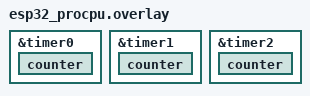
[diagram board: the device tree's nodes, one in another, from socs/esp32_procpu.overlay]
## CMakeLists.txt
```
# SPDX-License-Identifier: Apache-2.0

cmake_minimum_required(VERSION 3.28.0)

find_package(Zephyr REQUIRED HINTS $ENV{ZEPHYR_BASE})
project(esp_interrupt_test)

target_sources(app PRIVATE src/main.c src/noniram.c src/mli_encoding.c src/mli_dispatch.c)
target_include_directories(app PRIVATE ${ZEPHYR_BASE}/arch/common/include)
```

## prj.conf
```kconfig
CONFIG_ZTEST=y
CONFIG_COUNTER=y
CONFIG_DYNAMIC_INTERRUPTS=y
```

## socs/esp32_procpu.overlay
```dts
/*
 * Copyright (c) 2025-2026 Espressif Systems (Shanghai) Co., Ltd.
 *
 * SPDX-License-Identifier: Apache-2.0
 */

/*
 * Only enable the timers; their interrupt wiring is inherited from
 * esp32_common.dtsi, which routes each one through its own INTMUX node with a
 * single interrupt cell. Do not override "interrupts" here: the pre-INTMUX
 * <cpu_line source priority flags> form parses as four separate interrupts
 * against a 1-cell intmux and makes gen_isr_tables.py reject the build.
 */

&timer0 {
	status = "okay";

	counter {
		status = "okay";
	};
};

&timer1 {
	status = "okay";

	counter {
		status = "okay";
	};
};

&timer2 {
	status = "okay";

	counter {
		status = "okay";
	};
};
```

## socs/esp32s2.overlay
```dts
/*
 * Copyright (c) 2025-2026 Espressif Systems (Shanghai) Co., Ltd.
 *
 * SPDX-License-Identifier: Apache-2.0
 */

/*
 * Only enable the timers; their interrupt wiring is inherited from
 * esp32s2_common.dtsi, which routes each one through its own INTMUX node with a
 * single interrupt cell. Do not override "interrupts" here: the pre-INTMUX
 * <cpu_line source priority flags> form parses as four separate interrupts
 * against a 1-cell intmux and makes gen_isr_tables.py reject the build.
 */

&timer0 {
	status = "okay";

	counter {
		status = "okay";
	};
};

&timer1 {
	status = "okay";

	counter {
		status = "okay";
	};
};

&timer2 {
	status = "okay";

	counter {
		status = "okay";
	};
};
```

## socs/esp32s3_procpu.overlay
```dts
/*
 * Copyright (c) 2025 Espressif Systems (Shanghai) Co., Ltd.
 *
 * SPDX-License-Identifier: Apache-2.0
 */

&timer0 {
	status = "okay";

	counter {
		status = "okay";
	};
};

&timer1 {
	status = "okay";

	counter {
		status = "okay";
	};
};

&timer2 {
	status = "okay";

	counter {
		status = "okay";
	};
};
```

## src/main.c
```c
/*
 * Copyright (c) 2025 Espressif Systems (Shanghai) Co., Ltd.
 *
 * SPDX-License-Identifier: Apache-2.0
 */

#include <zephyr/kernel.h>
#include <zephyr/ztest.h>
#include <zephyr/device.h>
#include <zephyr/devicetree.h>
#include <zephyr/drivers/counter.h>
#include <zephyr/sys/printk.h>

#define COUNTER_INST_COUNT DT_NUM_INST_STATUS_OKAY(espressif_esp32_counter)

#if COUNTER_INST_COUNT >= 3

/* Test sets the three timer units, each with different interrupt priority level.
 * Each timer/counter is set to respond to three separate alarms.
 * The alarm times are set so each would trigger one after another separated by
 * the `ALARM_DIFF_US` time.
 * Each ISR sets its corresponding token into its token slots and wait for the
 * subsequent alarm ISR to be called.
 * After the last alarm ISR finishes the main loop checks if the ISR were called.
 */

#define TOKEN_A 0xBEEFBABE
#define TOKEN_B 0xC0FEB00B
#define TOKEN_C 0xDEAD5AA5

#define ALARM_DIFF_US 1000
#define ALARM_A_US    (1000 + ALARM_DIFF_US)
#define ALARM_B_US    (ALARM_A_US + ALARM_DIFF_US)
#define ALARM_C_US    (ALARM_B_US + ALARM_DIFF_US)
#define ISR_DELAY_US  (ALARM_DIFF_US * 3)
#define CYCLE_MS      10
#define TEST_CYCLES   1000

static const struct device *const timer0 = DEVICE_DT_GET(DT_INST(0, espressif_esp32_counter));
static const struct device *const timer1 = DEVICE_DT_GET(DT_INST(1, espressif_esp32_counter));
static const struct device *const timer2 = DEVICE_DT_GET(DT_INST(2, espressif_esp32_counter));

static struct counter_alarm_cfg alarm_a;
static struct counter_alarm_cfg alarm_b;
static struct counter_alarm_cfg alarm_c;

static int token[3];
static int success_cnt;
static int error_cnt;

static void alarm_handler_c(const struct device *dev, uint8_t chan_id, uint32_t counter,
			    void *user_data)
{
	if (dev == timer2 && token[0] == TOKEN_A && token[1] == TOKEN_B && token[2] == 0) {
		token[2] = TOKEN_C;
	}

	k_busy_wait(ISR_DELAY_US);
}

static void alarm_handler_b(const struct device *dev, uint8_t chan_id, uint32_t counter,
			    void *user_data)
{
	if (dev == timer1 && token[0] == TOKEN_A && token[1] == 0 && token[2] == 0) {
		token[1] = TOKEN_B;
	}

	k_busy_wait(ISR_DELAY_US);
}

static void alarm_handler_a(const struct device *dev, uint8_t chan_id, uint32_t counter,
			    void *user_data)
{
	if (dev == timer0 && token[0] == 0 && token[1] == 0 && token[2] == 0) {
		token[0] = TOKEN_A;
	}

	k_busy_wait(ISR_DELAY_US);
}

static void *esp_interrupt_suite_setup(void)
{
	zassert_true(device_is_ready(timer0), "Device %s not ready", timer0->name);
	zassert_true(device_is_ready(timer1), "Device %s not ready", timer1->name);
	zassert_true(device_is_ready(timer2), "Device %s not ready", timer2->name);

	zassert_false(counter_start(timer0), "Timer 0 failed to start");
	zassert_false(counter_start(timer1), "Timer 1 failed to start");
	zassert_false(counter_start(timer2), "Timer 2 failed to start");

	return NULL;
}


ZTEST(esp_interrupt, test_nested_isr)
{
	uint32_t cnt = TEST_CYCLES;

	success_cnt = 0;
	error_cnt = 0;

	while (cnt--) {
		alarm_a.ticks = counter_us_to_ticks(timer0, ALARM_A_US);
		alarm_a.callback = alarm_handler_a;

		alarm_b.ticks = counter_us_to_ticks(timer1, ALARM_B_US);
		alarm_b.callback = alarm_handler_b;

		alarm_c.ticks = counter_us_to_ticks(timer2, ALARM_C_US);
		alarm_c.callback = alarm_handler_c;

		counter_reset(timer0);
		counter_reset(timer1);
		counter_reset(timer2);

		zassert_false(counter_set_channel_alarm(timer0, 0, &alarm_a),
			      "Failed to set alarm A");
		zassert_false(counter_set_channel_alarm(timer1, 0, &alarm_b),
			      "Failed to set alarm B");
		zassert_false(counter_set_channel_alarm(timer2, 0, &alarm_c),
			      "Failed to set alarm C");

		k_msleep(CYCLE_MS);

		if (token[0] == TOKEN_A && token[1] == TOKEN_B && token[2] == TOKEN_C) {
			success_cnt++;
		} else {
			error_cnt++;
		}

		token[0] = 0;
		token[1] = 0;
		token[2] = 0;
	}

	zassert_true(error_cnt == 0, "Errors occurred (%d)", error_cnt);
	zassert_true(success_cnt == TEST_CYCLES, "Not all test cycles passed (%d from %d)",
		     success_cnt, TEST_CYCLES);
}

ZTEST_SUITE(esp_interrupt, NULL, esp_interrupt_suite_setup, NULL, NULL, NULL);

#endif /* COUNTER_INST_COUNT >= 3 */
```

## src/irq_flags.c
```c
/*
 * Copyright (c) 2026 Espressif Systems (Shanghai) Co., Ltd.
 *
 * SPDX-License-Identifier: Apache-2.0
 */

#include <zephyr/ztest.h>
#include <zephyr/irq.h>
#include <zephyr/sw_isr_table.h>
#include <esp_attr.h>
#include <esp_soc_irq.h>
#include <zephyr/drivers/interrupt_controller/intc_esp32.h>

#define TEST_IRQ_PRIORITY 1

static volatile int iram_isr_count;

static void IRAM_ATTR test_isr_iram_a(const void *arg)
{
	ARG_UNUSED(arg);
	iram_isr_count++;
}

static void IRAM_ATTR test_isr_iram_b(const void *arg)
{
	ARG_UNUSED(arg);
	iram_isr_count++;
}

static void test_isr_flash(const void *arg)
{
	ARG_UNUSED(arg);
	iram_isr_count++;
}

/*
 * Find a free CPU interrupt line. The search is bounded by SOC_CPU_INTR_NUM and
 * not by CONFIG_NUM_IRQS: only the first SOC_CPU_INTR_NUM table entries are CPU
 * lines, the rest being the level-2 source window and the level-3 windows. The
 * IRAM bookkeeping under test is indexed by CPU line, so handing it a slot from
 * one of the higher windows is meaningless and is rejected.
 */
static unsigned int find_unused_irq(void)
{
	unsigned int line;

	for (line = 0; line < SOC_CPU_INTR_NUM; line++) {
		unsigned int table_idx = line + CONFIG_GEN_IRQ_START_VECTOR;

		if (_sw_isr_table[table_idx].isr == z_irq_spurious) {
			return line;
		}
	}

	zassert_unreachable("No unused CPU interrupt line found");
	return 0;
}

ZTEST(esp_irq_flags, test_shared_iram_line_mask)
{
	unsigned int irq = find_unused_irq();
	int rc;

	rc = arch_irq_connect_dynamic(irq, TEST_IRQ_PRIORITY, test_isr_iram_a, NULL,
				      ESP_INTR_FLAG_IRAM);
	zassert_equal(rc, (int)irq, "first IRAM connect failed: %d", rc);
	zassert_equal(z_soc_irq_line_total_clients_get(irq), 1);
	zassert_equal(z_soc_irq_line_non_iram_clients_get(irq), 0);
	zassert_equal(z_soc_irq_non_iram_int_mask_get(irq), 0);

	rc = arch_irq_connect_dynamic(irq, TEST_IRQ_PRIORITY, test_isr_iram_b, NULL,
				      ESP_INTR_FLAG_IRAM);
	zassert_equal(rc, (int)irq, "second IRAM connect failed: %d", rc);
	zassert_equal(z_soc_irq_line_total_clients_get(irq), 2);
	zassert_equal(z_soc_irq_line_non_iram_clients_get(irq), 0);
	zassert_equal(z_soc_irq_non_iram_int_mask_get(irq), 0);

	rc = arch_irq_disconnect_dynamic(irq, TEST_IRQ_PRIORITY, test_isr_iram_a, NULL,
				       ESP_INTR_FLAG_IRAM);
	zassert_equal(rc, 0, "first IRAM disconnect failed: %d", rc);
	zassert_equal(z_soc_irq_line_total_clients_get(irq), 1);
	zassert_equal(z_soc_irq_non_iram_int_mask_get(irq), 0);

	rc = arch_irq_disconnect_dynamic(irq, TEST_IRQ_PRIORITY, test_isr_iram_b, NULL,
				       ESP_INTR_FLAG_IRAM);
	zassert_equal(rc, 0, "second IRAM disconnect failed: %d", rc);
	zassert_equal(z_soc_irq_line_total_clients_get(irq), 0);
	zassert_equal(z_soc_irq_non_iram_int_mask_get(irq), 0);
}

ZTEST(esp_irq_flags, test_shared_mixed_registration_rejected)
{
	unsigned int irq = find_unused_irq();
	int rc;

	rc = arch_irq_connect_dynamic(irq, TEST_IRQ_PRIORITY, test_isr_iram_a, NULL,
				      ESP_INTR_FLAG_IRAM);
	zassert_equal(rc, (int)irq, "IRAM connect failed: %d", rc);

	rc = arch_irq_connect_dynamic(irq, TEST_IRQ_PRIORITY, test_isr_flash, NULL, 0);
	zassert_equal(rc, -EINVAL, "mixed non-IRAM connect should fail");
	zassert_equal(z_soc_irq_line_total_clients_get(irq), 1);
	zassert_equal(z_soc_irq_non_iram_int_mask_get(irq), 0);

	rc = arch_irq_disconnect_dynamic(irq, TEST_IRQ_PRIORITY, test_isr_iram_a, NULL,
				       ESP_INTR_FLAG_IRAM);
	zassert_equal(rc, 0, "IRAM disconnect failed: %d", rc);
}

ZTEST(esp_irq_flags, test_shared_non_iram_sets_mask)
{
	unsigned int irq = find_unused_irq();
	int rc;

	rc = arch_irq_connect_dynamic(irq, TEST_IRQ_PRIORITY, test_isr_flash, NULL, 0);
	zassert_equal(rc, (int)irq, "non-IRAM connect failed: %d", rc);
	zassert_equal(z_soc_irq_line_non_iram_clients_get(irq), 1);
	zassert_equal(z_soc_irq_non_iram_int_mask_get(irq), 1);

	rc = arch_irq_disconnect_dynamic(irq, TEST_IRQ_PRIORITY, test_isr_flash, NULL, 0);
	zassert_equal(rc, 0, "non-IRAM disconnect failed: %d", rc);
	zassert_equal(z_soc_irq_line_total_clients_get(irq), 0);
	zassert_equal(z_soc_irq_non_iram_int_mask_get(irq), 0);
}

ZTEST(esp_irq_flags, test_iram_flag_requires_iram_handler)
{
	unsigned int irq = find_unused_irq();
	int rc;

	rc = arch_irq_connect_dynamic(irq, TEST_IRQ_PRIORITY, test_isr_flash, NULL,
				      ESP_INTR_FLAG_IRAM);
	zassert_equal(rc, -EINVAL, "flash handler with IRAM flag should fail");
}

ZTEST_SUITE(esp_irq_flags, NULL, NULL, NULL, NULL, NULL);
```

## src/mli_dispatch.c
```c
/*
 * Copyright (c) 2026 Espressif Systems (Shanghai) Co., Ltd.
 *
 * SPDX-License-Identifier: Apache-2.0
 */

#include <zephyr/ztest.h>
#include <zephyr/devicetree.h>
#include <zephyr/irq.h>
#include <zephyr/irq_multilevel.h>
#include <zephyr/sw_isr_table.h>
#include <sw_isr_common.h>

#if defined(CONFIG_MULTI_LEVEL_INTERRUPTS)

/* A level-2 IRQ has its slot at the start of the level-2 window plus its source */
ZTEST(mli_dispatch, test_level_2_slot)
{
	const unsigned int irqn = DT_IRQN(DT_NODELABEL(uart0));

	zassert_equal(z_get_sw_isr_table_idx(irqn),
		      CONFIG_2ND_LVL_ISR_TBL_OFFSET + DT_IRQ(DT_NODELABEL(uart0), irq));
}

#if DT_HAS_COMPAT_STATUS_OKAY(espressif_esp32_counter)
#define COUNTER_IRQN DT_IRQN(DT_PARENT(DT_INST(0, espressif_esp32_counter)))

ZTEST(mli_dispatch, test_connected_level_2_slot)
{
	const unsigned int idx = z_get_sw_isr_table_idx(COUNTER_IRQN);

	zassert_not_equal(_sw_isr_table[idx].isr, z_irq_spurious,
			  "the counter ISR must sit in its level-2 slot");
}

ZTEST(mli_dispatch, test_enable_state)
{
	zassert_true(irq_is_enabled(COUNTER_IRQN) != 0, "the counter driver enables its IRQ");

	irq_disable(COUNTER_IRQN);
	zassert_true(irq_is_enabled(COUNTER_IRQN) == 0);

	irq_enable(COUNTER_IRQN);
	zassert_true(irq_is_enabled(COUNTER_IRQN) != 0);
}
#endif

#if defined(CONFIG_3RD_LEVEL_INTERRUPTS) && DT_NODE_HAS_STATUS_OKAY(DT_NODELABEL(gpio0_l3_intc))
/*
 * A level-3 IRQ has its slot in the window of its aggregator, at the input
 * index. The GPIO driver is connected on the catch-all input.
 */
ZTEST(mli_dispatch, test_level_3_catch_all_slot)
{
	const unsigned int irqn = DT_IRQN(DT_NODELABEL(gpio0));
	unsigned int idx = z_get_sw_isr_table_idx(irqn);

	zassert_true(idx >= CONFIG_3RD_LVL_ISR_TBL_OFFSET);
	zassert_equal((idx - CONFIG_3RD_LVL_ISR_TBL_OFFSET) %
			      CONFIG_MAX_IRQ_PER_3RD_LEVEL_AGGREGATOR,
		      irq_from_level_3(irqn));
	zassert_not_equal(_sw_isr_table[idx].isr, z_irq_spurious,
			  "the GPIO ISR must sit in the catch-all slot");
	idx = z_get_sw_isr_table_idx(DT_IRQN(DT_NODELABEL(gpio0_l3_intc)));
	zassert_not_equal(_sw_isr_table[idx].isr, z_irq_spurious,
			  "the aggregator ISR must sit in its level-2 slot");
}
#endif

ZTEST_SUITE(mli_dispatch, NULL, NULL, NULL, NULL, NULL);

#endif /* CONFIG_MULTI_LEVEL_INTERRUPTS */
```

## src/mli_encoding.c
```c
/*
 * Copyright (c) 2026 Espressif Systems (Shanghai) Co., Ltd.
 *
 * SPDX-License-Identifier: Apache-2.0
 */

#include <zephyr/ztest.h>
#include <zephyr/devicetree.h>
#include <zephyr/irq_multilevel.h>
#include <zephyr/drivers/interrupt_controller/intc_esp32.h>
#include <zephyr/dt-bindings/interrupt-controller/espressif-esp32-l3-intc.h>

#if defined(CONFIG_MULTI_LEVEL_INTERRUPTS)

/* Every level-2 and level-3 IRQ carries the intmux key line in its level-1 field */
#define INTMUX_KEY_LINE DT_IRQ(DT_NODELABEL(intmux), irq)

ZTEST(mli_encoding, test_shared_consumer_is_level_2)
{
	const unsigned int irqn = DT_IRQN(DT_NODELABEL(uart0));

	zassert_equal(irq_get_level(irqn), 2U);
	zassert_equal(irq_from_level_2(irqn), DT_IRQ(DT_NODELABEL(uart0), irq),
		      "level-2 field must be the interrupt matrix source");
	zassert_equal(irq_parent_level_2(irqn), INTMUX_KEY_LINE);
}

ZTEST(mli_encoding, test_flags_cell)
{
	zassert_equal(DT_IRQ(DT_NODELABEL(uart0), flags) & ESP_INTR_FLAG_IRAM, 0,
		      "uart0 must not be marked ESP_INTR_FLAG_IRAM");
#if DT_NODE_HAS_STATUS_OKAY(DT_NODELABEL(systimer0))
	zassert_not_equal(DT_IRQ(DT_NODELABEL(systimer0), flags) & ESP_INTR_FLAG_IRAM, 0,
			  "the system tick must be marked ESP_INTR_FLAG_IRAM");
#endif
}

#if defined(CONFIG_3RD_LEVEL_INTERRUPTS) &&                                                       \
	(DT_NODE_EXISTS(DT_NODELABEL(rtc_l3_intc)) || DT_NODE_EXISTS(DT_NODELABEL(gpio0_l3_intc)))

static void check_level_3(unsigned int irqn, unsigned int input, unsigned int source)
{
	zassert_equal(irq_get_level(irqn), 3U);
	zassert_equal(irq_from_level_3(irqn), input, "level-3 field must be the input index");
	zassert_equal(irq_from_level_2(irqn), source,
		      "level-2 field must be the aggregator's source");
	zassert_equal(irq_parent_level_2(irqn), INTMUX_KEY_LINE);
}

#if DT_NODE_EXISTS(DT_NODELABEL(rtc_l3_intc))
ZTEST(mli_encoding, test_rtc_timer_is_level_3)
{
	check_level_3(DT_IRQN(DT_NODELABEL(rtc_timer)), DT_IRQ(DT_NODELABEL(rtc_timer), irq),
		      DT_IRQ(DT_NODELABEL(rtc_l3_intc), irq));
}
#endif

#if DT_NODE_EXISTS(DT_NODELABEL(gpio0_l3_intc))
BUILD_ASSERT(DT_PROP_LAST(DT_NODELABEL(gpio0_l3_intc), bits) == ESP_L3_CATCH_ALL,
	     "the last gpio0_l3_intc input must be ESP_L3_CATCH_ALL");

ZTEST(mli_encoding, test_gpio_is_catch_all_input)
{
	const unsigned int source = DT_IRQ(DT_NODELABEL(gpio0_l3_intc), irq);

	check_level_3(DT_IRQN(DT_NODELABEL(gpio0)),
		      DT_PROP_LEN(DT_NODELABEL(gpio0_l3_intc), bits) - 1U, source);
	check_level_3(DT_IRQN(DT_NODELABEL(ana_cmpr0)), 0U, source);
}
#endif

#endif /* CONFIG_3RD_LEVEL_INTERRUPTS && level-3 consumers */

ZTEST_SUITE(mli_encoding, NULL, NULL, NULL, NULL, NULL);

#endif /* CONFIG_MULTI_LEVEL_INTERRUPTS */
```

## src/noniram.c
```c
/*
 * Copyright (c) 2026 Espressif Systems (Shanghai) Co., Ltd.
 *
 * SPDX-License-Identifier: Apache-2.0
 */

/*
 * esp_intr_noniram_disable() masks every CPU line not marked
 * ESP_INTR_FLAG_IRAM in the devicetree, and esp_intr_noniram_enable() unmasks
 * it. A timer group alarm is level-triggered and stays pending until its ISR
 * clears it, so an alarm raised during the pause fires once on resume. Nothing
 * is asserted while paused: a failed assertion would leave the pause active.
 */

#include <zephyr/ztest.h>
#include <zephyr/device.h>
#include <zephyr/devicetree.h>
#include <zephyr/irq.h>
#include <zephyr/drivers/counter.h>
#include <zephyr/drivers/interrupt_controller/intc_esp32.h>

#define COUNTER_NODE DT_INST(0, espressif_esp32_counter)

#if DT_NODE_HAS_STATUS_OKAY(COUNTER_NODE)

#define COUNTER_TIMER DT_PARENT(COUNTER_NODE)
#define COUNTER_IRQN  DT_IRQN(COUNTER_TIMER)
#define ALARM_US      100U
#define WAIT_US       2000U

BUILD_ASSERT((DT_IRQ(COUNTER_TIMER, flags) & ESP_INTR_FLAG_IRAM) == 0,
	     "the test needs a counter that is paused during flash operations");

static const struct device *const counter = DEVICE_DT_GET(COUNTER_NODE);
static volatile uint32_t alarm_hits;

static void alarm_cb(const struct device *dev, uint8_t chan_id, uint32_t ticks, void *user_data)
{
	ARG_UNUSED(dev);
	ARG_UNUSED(chan_id);
	ARG_UNUSED(ticks);
	ARG_UNUSED(user_data);

	alarm_hits++;
}

static int arm_alarm(void)
{
	struct counter_alarm_cfg cfg = {
		.callback = alarm_cb,
		.ticks = counter_us_to_ticks(counter, ALARM_US),
	};

	return counter_set_channel_alarm(counter, 0, &cfg);
}

static void esp_noniram_before(void *fixture)
{
	ARG_UNUSED(fixture);

	zassert_true(device_is_ready(counter), "Device %s not ready", counter->name);
	(void)counter_start(counter);
	irq_enable(COUNTER_IRQN);
	alarm_hits = 0U;
}

static void esp_noniram_after(void *fixture)
{
	ARG_UNUSED(fixture);

	(void)counter_cancel_channel_alarm(counter, 0);
	irq_enable(COUNTER_IRQN);
}

ZTEST(esp_noniram, test_paused_source_fires_on_resume)
{
	uint32_t hits_paused;
	int enabled_paused;
	int err;

	esp_intr_noniram_disable();
	err = arm_alarm();
	k_busy_wait(WAIT_US);
	hits_paused = alarm_hits;
	enabled_paused = irq_is_enabled(COUNTER_IRQN);
	esp_intr_noniram_enable();
	k_busy_wait(WAIT_US);

	zassert_equal(err, 0, "alarm not set: %d", err);
	zassert_equal(hits_paused, 0U, "the alarm fired while paused");
	zassert_not_equal(enabled_paused, 0, "a paused IRQ must read as enabled");
	zassert_equal(alarm_hits, 1U, "the alarm must fire once on resume");
}

ZTEST(esp_noniram, test_disable_while_paused_holds_on_resume)
{
	uint32_t hits_disabled;
	int enabled_disabled;
	int err;

	esp_intr_noniram_disable();
	irq_disable(COUNTER_IRQN);
	esp_intr_noniram_enable();
	err = arm_alarm();
	k_busy_wait(WAIT_US);
	hits_disabled = alarm_hits;
	enabled_disabled = irq_is_enabled(COUNTER_IRQN);
	irq_enable(COUNTER_IRQN);
	k_busy_wait(WAIT_US);

	zassert_equal(err, 0, "alarm not set: %d", err);
	zassert_equal(hits_disabled, 0U, "the resume re-enabled a disabled IRQ");
	zassert_equal(enabled_disabled, 0, "a disabled IRQ must read as disabled");
	zassert_equal(alarm_hits, 1U, "the alarm must fire once on irq_enable()");
}

ZTEST(esp_noniram, test_enable_while_paused_waits_for_resume)
{
	uint32_t hits_paused;
	int err;

	irq_disable(COUNTER_IRQN);
	esp_intr_noniram_disable();
	irq_enable(COUNTER_IRQN);
	err = arm_alarm();
	k_busy_wait(WAIT_US);
	hits_paused = alarm_hits;
	esp_intr_noniram_enable();
	k_busy_wait(WAIT_US);

	zassert_equal(err, 0, "alarm not set: %d", err);
	zassert_equal(hits_paused, 0U, "irq_enable() bypassed the pause");
	zassert_equal(alarm_hits, 1U, "the alarm must fire once on resume");
}

ZTEST_SUITE(esp_noniram, NULL, NULL, esp_noniram_before, esp_noniram_after, NULL);

#endif /* counter okay */
```
